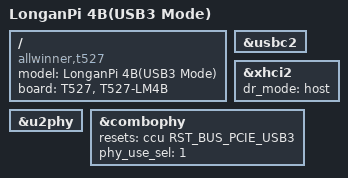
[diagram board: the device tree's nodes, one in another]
/*
 * Allwinner Technology CO., Ltd.
 */

/dts-v1/;

#include "sun55i-t527-longanpi-4b.dtsi"

/{
	model = "LonganPi 4B(USB3 Mode)";
	board = "T527", "T527-LM4B";
	compatible = "allwinner,t527", "arm,sun55iw3p1", "Sipeed,T527-LM4B";
};

&usbc2 {
	device_type = "usbc2";
	status = "okay";
};

&xhci2 {
	dr_mode = "host";
	status = "okay";
};

&u2phy {
	status = "okay";
};

&combophy {
	resets = <&ccu RST_BUS_PCIE_USB3>;
	phy_use_sel = <1>; /* 0:PCIE; 1:USB3; 2:PCIE_USB3_U2 */
	status = "okay";
};
